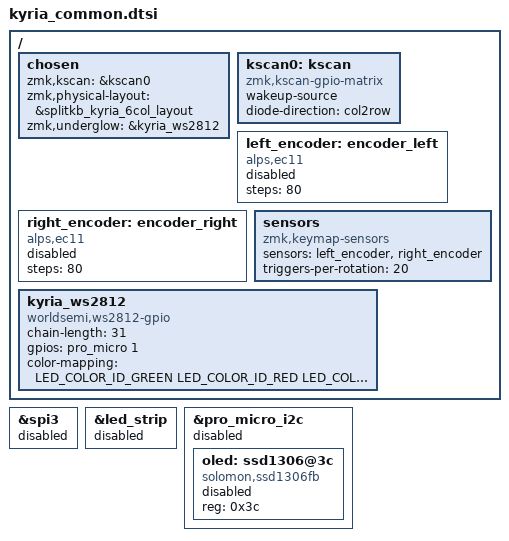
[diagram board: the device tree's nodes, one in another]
/*
 * Copyright (c) 2022 The ZMK Contributors
 *
 * SPDX-License-Identifier: MIT
 */

#include <dt-bindings/zmk/matrix_transform.h>
#include <dt-bindings/led/led.h>

#include "kyria-layouts.dtsi"

/ {
    chosen {
        /* zephyr,display is set by the nice_view shield overlay */
        zmk,kscan = &kscan0;
        zmk,physical-layout = &splitkb_kyria_6col_layout;
    };

    kscan0: kscan {
        compatible = "zmk,kscan-gpio-matrix";
        wakeup-source;

        diode-direction = "col2row";
    };

    left_encoder: encoder_left {
        compatible = "alps,ec11";
        steps = <80>;
        status = "disabled";
    };

    right_encoder: encoder_right {
        compatible = "alps,ec11";
        steps = <80>;
        status = "disabled";
    };

    sensors: sensors {
        compatible = "zmk,keymap-sensors";
        sensors = <&left_encoder &right_encoder>;
        triggers-per-rotation = <20>;
    };

    /* Underglow / per-key RGB: the factory Kyria rev3 LED chain (DIN wired to
     * Pro Micro D3/P0.20 on the PCB). ZMK's kyria nice!nano board overlay
     * defines an SPI-backed strip on P0.06 — kill it (P0.06 must stay free)
     * and bit-bang the chain from D1 (where the factory LED wire actually lands). chain-length=31 = 25 per-key
     * SK6812 + 6 underglow WS2812B (matches the old &led_strip setting).
     */
    kyria_ws2812: kyria_ws2812 {
        compatible = "worldsemi,ws2812-gpio";
        chain-length = <31>;
        gpios = <&pro_micro 1 GPIO_ACTIVE_HIGH>; /* D1 = factory LED DIN net (P0.06) */
        color-mapping = <LED_COLOR_ID_GREEN LED_COLOR_ID_RED LED_COLOR_ID_BLUE>;
    };
};

/ {
    chosen {
        zmk,underglow = &kyria_ws2812;
    };
};

/* Stock SPI ws2812 on spi3/P0.06 from kyria/boards/nice_nano_nrf52840_zmk.overlay */
&spi3 {
    status = "disabled";
};

&led_strip {
    status = "disabled";
};

/* SSD1306 I2C OLED removed in favour of nice!view (SPI).
 * The OLED socket's VCC/GND are still used to power the nice!view.
 * Keep the old node around (disabled) so nothing else breaks on &oled.
 */
&pro_micro_i2c {
    status = "disabled";

    oled: ssd1306@3c {
        compatible = "solomon,ssd1306fb";
        reg = <0x3c>;
        status = "disabled";
    };
};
